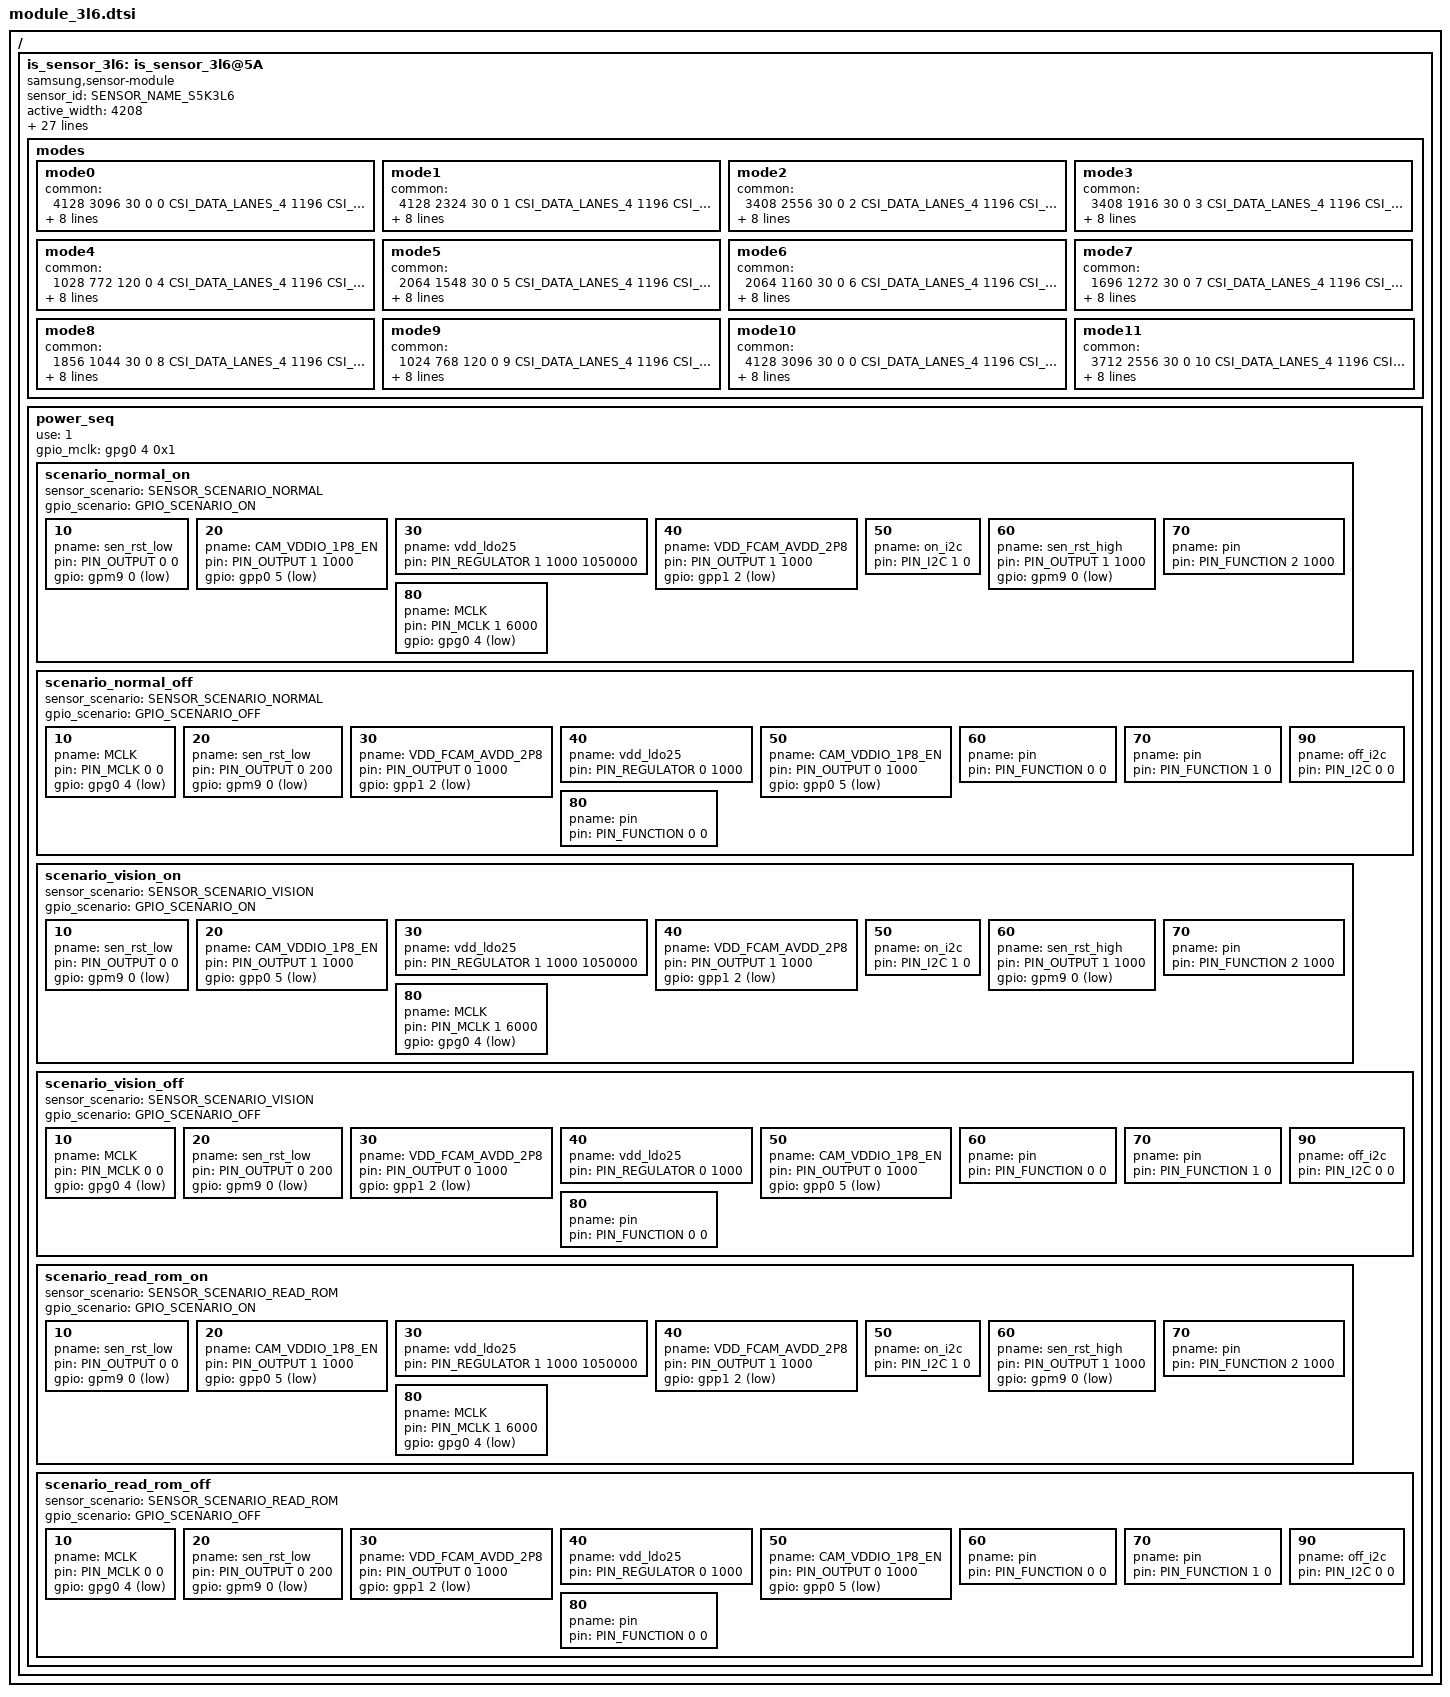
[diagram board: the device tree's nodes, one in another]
/*
 * SAMSUNG EXYNOSxxxx board camera device tree source
 *
 * Copyright (c) 2022 Samsung Electronics Co., Ltd.
 *		http://www.samsung.com
 *
 * This program is free software; you can redistribute it and/or modify
 * it under the terms of the GNU General Public License version 2 as
 * published by the Free Software Foundation.
 */

#include <dt-bindings/camera/exynos_is_dt.h>


/ {
	fragment@camera {
		target-path = "/";
		__overlay__ {
			is_sensor_3l6: is_sensor_3l6@5A {
				compatible = "samsung,sensor-module";

				/* common */
				sensor_id = <SENSOR_NAME_S5K3L6>;
				active_width = <4208>;
				active_height = <3120>;
				margin_left = <0>;
				margin_right = <0>;
				margin_top = <0>;
				margin_bottom = <0>;
				max_framerate = <120>;
				bitwidth = <10>;
				use_retention_mode = <SENSOR_RETENTION_UNSUPPORTED>;
				sensor_maker = "SLSI";
				sensor_name = "S5K3L6";
				setfile_name = "setfile_3l6.bin";
				pinning_setfile;
				preload_setfile;

				status = "okay";

				/* board */
				pinctrl-names = "pin0", "pin1", "pin2", "release";
				pinctrl-0 = <>;
				pinctrl-1 = <&sensor_mclk2_out>;
				pinctrl-2 = <&sensor_mclk2_fn>;
				pinctrl-3 = <>;

				position = <1>; /* Rear:0. Front:1, Tele:2 */
				id = <1>; /* is_sensor id */
				mclk_ch = <2>;
				sensor_i2c_ch = <0>; /* SENSOR_CONTROL_I2C1 */

				/* vendor */
				rom_type = <3>; /* ROM_TYPE_OTPROM */
				rom_id = <1>;
				rom_cal_index = <0>;
				rom_dualcal_id = <0>;
				rom_dualcal_index = <0>;

				/* sensor modes */
				modes {
						/* common = <width, height, fps, settle, mode, lane, speed, interleave, lrte, pd_mode> */
						/* vcX = <map, hwformat, width, height, hwformat, type, width, height> */
						mode0 {
							common = <4128 3096 30 0 0 CSI_DATA_LANES_4 1196 CSI_MODE_VC_ONLY LRTE_DISABLE PD_NONE EX_NONE>;
							vc0 = </* in */ 0 HW_FORMAT_RAW10 4128 3096    /* out */ HW_FORMAT_RAW10 VC_NOTHING 4128 3096>;
							vc1 = </* in */ 1 HW_FORMAT_UNKNOWN 0 0        /* out */ HW_FORMAT_UNKNOWN VC_NOTHING 0 0>;
							vc2 = </* in */ 2 HW_FORMAT_UNKNOWN 0 0        /* out */ HW_FORMAT_UNKNOWN VC_NOTHING 0 0>;
							vc3 = </* in */ 3 HW_FORMAT_UNKNOWN 0 0        /* out */ HW_FORMAT_UNKNOWN VC_NOTHING 0 0>;
						};
						mode1 {
							common = <4128 2324 30 0 1 CSI_DATA_LANES_4 1196 CSI_MODE_VC_ONLY LRTE_DISABLE PD_NONE EX_NONE>;
							vc0 = </* in */ 0 HW_FORMAT_RAW10 4128 2324    /* out */ HW_FORMAT_RAW10 VC_NOTHING 4128 2324>;
							vc1 = </* in */ 1 HW_FORMAT_UNKNOWN 0 0        /* out */ HW_FORMAT_UNKNOWN VC_NOTHING 0 0>;
							vc2 = </* in */ 2 HW_FORMAT_UNKNOWN 0 0        /* out */ HW_FORMAT_UNKNOWN VC_NOTHING 0 0>;
							vc3 = </* in */ 3 HW_FORMAT_UNKNOWN 0 0        /* out */ HW_FORMAT_UNKNOWN VC_NOTHING 0 0>;
						};
						mode2 {
							common = <3408 2556 30 0 2 CSI_DATA_LANES_4 1196 CSI_MODE_VC_ONLY LRTE_DISABLE PD_NONE EX_NONE>;
							vc0 = </* in */ 0 HW_FORMAT_RAW10 3408 2556    /* out */ HW_FORMAT_RAW10 VC_NOTHING 3408 2556>;
							vc1 = </* in */ 1 HW_FORMAT_UNKNOWN 0 0        /* out */ HW_FORMAT_UNKNOWN VC_NOTHING 0 0>;
							vc2 = </* in */ 2 HW_FORMAT_UNKNOWN 0 0        /* out */ HW_FORMAT_UNKNOWN VC_NOTHING 0 0>;
							vc3 = </* in */ 3 HW_FORMAT_UNKNOWN 0 0        /* out */ HW_FORMAT_UNKNOWN VC_NOTHING 0 0>;
						};
						mode3 {
							common = <3408 1916 30 0 3 CSI_DATA_LANES_4 1196 CSI_MODE_VC_ONLY LRTE_DISABLE PD_NONE EX_NONE>;
							vc0 = </* in */ 0 HW_FORMAT_RAW10 3408 1916    /* out */ HW_FORMAT_RAW10 VC_NOTHING 3408 1916>;
							vc1 = </* in */ 1 HW_FORMAT_UNKNOWN 0 0        /* out */ HW_FORMAT_UNKNOWN VC_NOTHING 0 0>;
							vc2 = </* in */ 2 HW_FORMAT_UNKNOWN 0 0        /* out */ HW_FORMAT_UNKNOWN VC_NOTHING 0 0>;
							vc3 = </* in */ 3 HW_FORMAT_UNKNOWN 0 0        /* out */ HW_FORMAT_UNKNOWN VC_NOTHING 0 0>;
						};
						mode4 {
							common = <1028 772 120 0 4 CSI_DATA_LANES_4 1196 CSI_MODE_VC_ONLY LRTE_DISABLE PD_NONE EX_NONE>;
							vc0 = </* in */ 0 HW_FORMAT_RAW10 1028 772    /* out */ HW_FORMAT_RAW10 VC_NOTHING 1028 772>;
							vc1 = </* in */ 1 HW_FORMAT_UNKNOWN 0 0        /* out */ HW_FORMAT_UNKNOWN VC_NOTHING 0 0>;
							vc2 = </* in */ 2 HW_FORMAT_UNKNOWN 0 0        /* out */ HW_FORMAT_UNKNOWN VC_NOTHING 0 0>;
							vc3 = </* in */ 3 HW_FORMAT_UNKNOWN 0 0        /* out */ HW_FORMAT_UNKNOWN VC_NOTHING 0 0>;
						};
						mode5 {
							common = <2064 1548 30 0 5 CSI_DATA_LANES_4 1196 CSI_MODE_VC_ONLY LRTE_DISABLE PD_NONE EX_NONE>;
							vc0 = </* in */ 0 HW_FORMAT_RAW10 2064 1548    /* out */ HW_FORMAT_RAW10 VC_NOTHING 2064 1548>;
							vc1 = </* in */ 1 HW_FORMAT_UNKNOWN 0 0        /* out */ HW_FORMAT_UNKNOWN VC_NOTHING 0 0>;
							vc2 = </* in */ 2 HW_FORMAT_UNKNOWN 0 0        /* out */ HW_FORMAT_UNKNOWN VC_NOTHING 0 0>;
							vc3 = </* in */ 3 HW_FORMAT_UNKNOWN 0 0        /* out */ HW_FORMAT_UNKNOWN VC_NOTHING 0 0>;
						};
						mode6 {
							common = <2064 1160 30 0 6 CSI_DATA_LANES_4 1196 CSI_MODE_VC_ONLY LRTE_DISABLE PD_NONE EX_NONE>;
							vc0 = </* in */ 0 HW_FORMAT_RAW10 2064 1160    /* out */ HW_FORMAT_RAW10 VC_NOTHING 2064 1160>;
							vc1 = </* in */ 1 HW_FORMAT_UNKNOWN 0 0        /* out */ HW_FORMAT_UNKNOWN VC_NOTHING 0 0>;
							vc2 = </* in */ 2 HW_FORMAT_UNKNOWN 0 0        /* out */ HW_FORMAT_UNKNOWN VC_NOTHING 0 0>;
							vc3 = </* in */ 3 HW_FORMAT_UNKNOWN 0 0        /* out */ HW_FORMAT_UNKNOWN VC_NOTHING 0 0>;
						};
						mode7 {
							common = <1696 1272 30 0 7 CSI_DATA_LANES_4 1196 CSI_MODE_VC_ONLY LRTE_DISABLE PD_NONE EX_NONE>;
							vc0 = </* in */ 0 HW_FORMAT_RAW10 1696 1272    /* out */ HW_FORMAT_RAW10 VC_NOTHING 1696 1272>;
							vc1 = </* in */ 1 HW_FORMAT_UNKNOWN 0 0        /* out */ HW_FORMAT_UNKNOWN VC_NOTHING 0 0>;
							vc2 = </* in */ 2 HW_FORMAT_UNKNOWN 0 0        /* out */ HW_FORMAT_UNKNOWN VC_NOTHING 0 0>;
							vc3 = </* in */ 3 HW_FORMAT_UNKNOWN 0 0        /* out */ HW_FORMAT_UNKNOWN VC_NOTHING 0 0>;
						};
						mode8 {
							common = <1856 1044 30 0 8 CSI_DATA_LANES_4 1196 CSI_MODE_VC_ONLY LRTE_DISABLE PD_NONE EX_NONE>;
							vc0 = </* in */ 0 HW_FORMAT_RAW10 1856 1044    /* out */ HW_FORMAT_RAW10 VC_NOTHING 1856 1044>;
							vc1 = </* in */ 1 HW_FORMAT_UNKNOWN 0 0        /* out */ HW_FORMAT_UNKNOWN VC_NOTHING 0 0>;
							vc2 = </* in */ 2 HW_FORMAT_UNKNOWN 0 0        /* out */ HW_FORMAT_UNKNOWN VC_NOTHING 0 0>;
							vc3 = </* in */ 3 HW_FORMAT_UNKNOWN 0 0        /* out */ HW_FORMAT_UNKNOWN VC_NOTHING 0 0>;
						};
						mode9 {
							common = <1024 768 120 0 9 CSI_DATA_LANES_4 1196 CSI_MODE_VC_ONLY LRTE_DISABLE PD_NONE EX_NONE>;
							vc0 = </* in */ 0 HW_FORMAT_RAW10 1024 768    /* out */ HW_FORMAT_RAW10 VC_NOTHING 1024 768>;
							vc1 = </* in */ 1 HW_FORMAT_UNKNOWN 0 0        /* out */ HW_FORMAT_UNKNOWN VC_NOTHING 0 0>;
							vc2 = </* in */ 2 HW_FORMAT_UNKNOWN 0 0        /* out */ HW_FORMAT_UNKNOWN VC_NOTHING 0 0>;
							vc3 = </* in */ 3 HW_FORMAT_UNKNOWN 0 0        /* out */ HW_FORMAT_UNKNOWN VC_NOTHING 0 0>;
						};
						mode10 { //FOR SECURE CAMERA FD SCENARIO
							common = <4128 3096 30 0 0 CSI_DATA_LANES_4 1196 CSI_MODE_VC_ONLY LRTE_DISABLE PD_NONE EX_PDSTAT_OFF>;
							vc0 = </* in */ 0 HW_FORMAT_RAW10 4128 3096	/* out */ HW_FORMAT_RAW10 VC_NOTHING 2064 1548>;
							vc1 = </* in */ 1 HW_FORMAT_UNKNOWN 0 0		/* out */ HW_FORMAT_UNKNOWN VC_NOTHING 0 0>;
							vc2 = </* in */ 2 HW_FORMAT_UNKNOWN 0 0		/* out */ HW_FORMAT_UNKNOWN VC_NOTHING 0 0>;
							vc3 = </* in */ 3 HW_FORMAT_UNKNOWN 0 0		/* out */ HW_FORMAT_UNKNOWN VC_NOTHING 0 0>;
						};
						mode11 {
							common = <3712 2556 30 0 10 CSI_DATA_LANES_4 1196 CSI_MODE_VC_ONLY LRTE_DISABLE PD_NONE EX_NONE>;
							vc0 = </* in */ 0 HW_FORMAT_RAW10 3712 2556	/* out */ HW_FORMAT_RAW10 VC_NOTHING 3712 2556>;
							vc1 = </* in */ 1 HW_FORMAT_UNKNOWN 0 0		/* out */ HW_FORMAT_UNKNOWN VC_NOTHING 0 0>;
							vc2 = </* in */ 2 HW_FORMAT_UNKNOWN 0 0		/* out */ HW_FORMAT_UNKNOWN VC_NOTHING 0 0>;
							vc3 = </* in */ 3 HW_FORMAT_UNKNOWN 0 0		/* out */ HW_FORMAT_UNKNOWN VC_NOTHING 0 0>;
						};
				};

				power_seq {
					use = <1>;
					gpio_mclk = <&gpg0 4 0x1>;
					scenario_normal_on {
						sensor_scenario = <SENSOR_SCENARIO_NORMAL>;
						gpio_scenario = <GPIO_SCENARIO_ON>;

						/* A start node number should be over the 10 for reserved number 0~9. */
						/* pname = "name"; pin = <act value delay voltage>; gpio = <gpx# # 0x1>; */
						10 { pname = "sen_rst_low"; pin = <PIN_OUTPUT 0 0>; gpio = <&gpm9 0 0x1>; };
						20 { pname = "CAM_VDDIO_1P8_EN"; pin = <PIN_OUTPUT 1 1000>; gpio = <&gpp0 5 0x1>; };
						30 { pname = "vdd_ldo25"; pin = <PIN_REGULATOR 1 1000 1050000>; };
						40 { pname = "VDD_FCAM_AVDD_2P8"; pin = <PIN_OUTPUT 1 1000>; gpio = <&gpp1 2 0x1>; };
						50 { pname = "on_i2c"; pin = <PIN_I2C 1 0>; };
						60 { pname = "sen_rst_high"; pin = <PIN_OUTPUT 1 1000>; gpio = <&gpm9 0 0x1>; };
						70 { pname = "pin"; pin = <PIN_FUNCTION 2 1000>; };
						80 { pname = "MCLK"; pin = <PIN_MCLK 1 6000>; gpio = <&gpg0 4 0x1>; };
					};

					scenario_normal_off {
						sensor_scenario = <SENSOR_SCENARIO_NORMAL>;
						gpio_scenario = <GPIO_SCENARIO_OFF>;

						/* A start node number should be over the 10 for reserved number 0~9. */
						/* pname = "name"; pin = <act value delay voltage>; gpio = <gpx# # 0x1>; */
						10 { pname = "MCLK"; pin = <PIN_MCLK 0 0>; gpio = <&gpg0 4 0x1>; };
						20 { pname = "sen_rst_low"; pin = <PIN_OUTPUT 0 200>; gpio = <&gpm9 0 0x1>; };
						30 { pname = "VDD_FCAM_AVDD_2P8"; pin = <PIN_OUTPUT 0 1000>; gpio = <&gpp1 2 0x1>; };
						40 { pname = "vdd_ldo25"; pin = <PIN_REGULATOR 0 1000>; };
						50 { pname = "CAM_VDDIO_1P8_EN"; pin = <PIN_OUTPUT 0 1000>; gpio = <&gpp0 5 0x1>; };
						60 { pname = "pin"; pin = <PIN_FUNCTION 0 0>; };
						70 { pname = "pin"; pin = <PIN_FUNCTION 1 0>; };
						80 { pname = "pin"; pin = <PIN_FUNCTION 0 0>; };
						90 { pname = "off_i2c"; pin = <PIN_I2C 0 0>; };
					};

					scenario_vision_on {
						sensor_scenario = <SENSOR_SCENARIO_VISION>;
						gpio_scenario = <GPIO_SCENARIO_ON>;

						/* A start node number should be over the 10 for reserved number 0~9. */
						/* pname = "name"; pin = <act value delay voltage>; gpio = <gpx# # 0x1>; */
						10 { pname = "sen_rst_low"; pin = <PIN_OUTPUT 0 0>; gpio = <&gpm9 0 0x1>; };
						20 { pname = "CAM_VDDIO_1P8_EN"; pin = <PIN_OUTPUT 1 1000>; gpio = <&gpp0 5 0x1>; };
						30 { pname = "vdd_ldo25"; pin = <PIN_REGULATOR 1 1000 1050000>; };
						40 { pname = "VDD_FCAM_AVDD_2P8"; pin = <PIN_OUTPUT 1 1000>; gpio = <&gpp1 2 0x1>; };
						50 { pname = "on_i2c"; pin = <PIN_I2C 1 0>; };
						60 { pname = "sen_rst_high"; pin = <PIN_OUTPUT 1 1000>; gpio = <&gpm9 0 0x1>; };
						70 { pname = "pin"; pin = <PIN_FUNCTION 2 1000>; };
						80 { pname = "MCLK"; pin = <PIN_MCLK 1 6000>; gpio = <&gpg0 4 0x1>; };
					};

					scenario_vision_off {
						sensor_scenario = <SENSOR_SCENARIO_VISION>;
						gpio_scenario = <GPIO_SCENARIO_OFF>;

						/* A start node number should be over the 10 for reserved number 0~9. */
						/* pname = "name"; pin = <act value delay voltage>; gpio = <gpx# # 0x1>; */
						10 { pname = "MCLK"; pin = <PIN_MCLK 0 0>; gpio = <&gpg0 4 0x1>; };
						20 { pname = "sen_rst_low"; pin = <PIN_OUTPUT 0 200>; gpio = <&gpm9 0 0x1>; };
						30 { pname = "VDD_FCAM_AVDD_2P8"; pin = <PIN_OUTPUT 0 1000>; gpio = <&gpp1 2 0x1>; };
						40 { pname = "vdd_ldo25"; pin = <PIN_REGULATOR 0 1000>; };
						50 { pname = "CAM_VDDIO_1P8_EN"; pin = <PIN_OUTPUT 0 1000>; gpio = <&gpp0 5 0x1>; };
						60 { pname = "pin"; pin = <PIN_FUNCTION 0 0>; };
						70 { pname = "pin"; pin = <PIN_FUNCTION 1 0>; };
						80 { pname = "pin"; pin = <PIN_FUNCTION 0 0>; };
						90 { pname = "off_i2c"; pin = <PIN_I2C 0 0>; };
					};

					scenario_read_rom_on {
						sensor_scenario = <SENSOR_SCENARIO_READ_ROM>;
						gpio_scenario = <GPIO_SCENARIO_ON>;

						/* A start node number should be over the 10 for reserved number 0~9. */
						/* pname = "name"; pin = <act value delay voltage>; gpio = <gpx# # 0x1>; */
						10 { pname = "sen_rst_low"; pin = <PIN_OUTPUT 0 0>; gpio = <&gpm9 0 0x1>; };
						20 { pname = "CAM_VDDIO_1P8_EN"; pin = <PIN_OUTPUT 1 1000>; gpio = <&gpp0 5 0x1>; };
						30 { pname = "vdd_ldo25"; pin = <PIN_REGULATOR 1 1000 1050000>; };
						40 { pname = "VDD_FCAM_AVDD_2P8"; pin = <PIN_OUTPUT 1 1000>; gpio = <&gpp1 2 0x1>; };
						50 { pname = "on_i2c"; pin = <PIN_I2C 1 0>; };
						60 { pname = "sen_rst_high"; pin = <PIN_OUTPUT 1 1000>; gpio = <&gpm9 0 0x1>; };
						70 { pname = "pin"; pin = <PIN_FUNCTION 2 1000>; };
						80 { pname = "MCLK"; pin = <PIN_MCLK 1 6000>; gpio = <&gpg0 4 0x1>; };
					};

					scenario_read_rom_off {
						sensor_scenario = <SENSOR_SCENARIO_READ_ROM>;
						gpio_scenario = <GPIO_SCENARIO_OFF>;

						/* A start node number should be over the 10 for reserved number 0~9. */
						/* pname = "name"; pin = <act value delay voltage>; gpio = <gpx# # 0x1>; */
						10 { pname = "MCLK"; pin = <PIN_MCLK 0 0>; gpio = <&gpg0 4 0x1>; };
						20 { pname = "sen_rst_low"; pin = <PIN_OUTPUT 0 200>; gpio = <&gpm9 0 0x1>; };
						30 { pname = "VDD_FCAM_AVDD_2P8"; pin = <PIN_OUTPUT 0 1000>; gpio = <&gpp1 2 0x1>; };
						40 { pname = "vdd_ldo25"; pin = <PIN_REGULATOR 0 1000>; };
						50 { pname = "CAM_VDDIO_1P8_EN"; pin = <PIN_OUTPUT 0 1000>; gpio = <&gpp0 5 0x1>; };
						60 { pname = "pin"; pin = <PIN_FUNCTION 0 0>; };
						70 { pname = "pin"; pin = <PIN_FUNCTION 1 0>; };
						80 { pname = "pin"; pin = <PIN_FUNCTION 0 0>; };
						90 { pname = "off_i2c"; pin = <PIN_I2C 0 0>; };
					};
				};
			};
		}; /* end of __overlay__ */

	}; /* end of fragment */
}; /* end of root */
